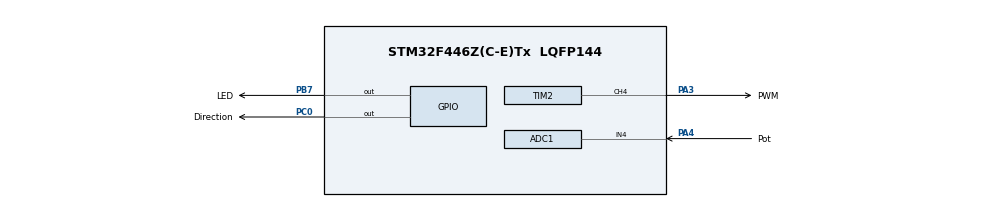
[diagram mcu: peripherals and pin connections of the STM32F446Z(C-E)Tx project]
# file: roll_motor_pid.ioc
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ADC1.Channel-2\#ChannelRegularConversion=ADC_CHANNEL_4
ADC1.ContinuousConvMode=ENABLE
ADC1.DMAContinuousRequests=ENABLE
ADC1.NbrOfConversionFlag=1
ADC1.Rank-2\#ChannelRegularConversion=1
ADC1.SamplingTime-2\#ChannelRegularConversion=ADC_SAMPLETIME_84CYCLES
ADC1.master=1
Dma.ADC1.0.Direction=DMA_PERIPH_TO_MEMORY
Dma.ADC1.0.FIFOMode=DMA_FIFOMODE_DISABLE
Dma.ADC1.0.Instance=DMA2_Stream0
Dma.ADC1.0.MemDataAlignment=DMA_MDATAALIGN_HALFWORD
Dma.ADC1.0.MemInc=DMA_MINC_ENABLE
Dma.ADC1.0.Mode=DMA_CIRCULAR
Dma.ADC1.0.PeriphDataAlignment=DMA_PDATAALIGN_HALFWORD
Dma.ADC1.0.PeriphInc=DMA_PINC_DISABLE
Dma.ADC1.0.Priority=DMA_PRIORITY_LOW
Dma.Request0=ADC1
Mcu.Family=STM32F4
Mcu.Name=STM32F446Z(C-E)Tx
Mcu.Package=LQFP144
NVIC.DMA2_Stream0_IRQn=true\:0\:0\:false\:false\:true\:false\:true\:true
NVIC.PriorityGroup=NVIC_PRIORITYGROUP_4
PA13.Mode=Serial_Wire
PA13.Signal=SYS_JTMS-SWDIO
PA14.Mode=Serial_Wire
PA14.Signal=SYS_JTCK-SWCLK
PA3.GPIO_Label=PWM
PA3.Signal=S_TIM2_CH4
PA4.GPIO_Label=Pot
PA4.Signal=ADCx_IN4
PB7.GPIO_Label=LED
PB7.Signal=GPIO_Output
PC0.GPIO_Label=Direction
PC0.Signal=GPIO_Output
ProjectManager.HeapSize=0x200
ProjectManager.StackSize=0x400
ProjectManager.TargetToolchain=STM32CubeIDE
RCC.CortexFreq_Value=16000000
RCC.USBFreq_Value=96000000
RCC.VCOOutputFreq_Value=192000000
SH.ADCx_IN4.0=ADC1_IN4,IN4
SH.S_TIM2_CH4.0=TIM2_CH4,PWM Generation4 CH4
TIM2.AutoReloadPreload=TIM_AUTORELOAD_PRELOAD_ENABLE
TIM2.Channel-PWM\ Generation4\ CH4=TIM_CHANNEL_4
TIM2.Period=799
TIM2.Pulse-PWM\ Generation4\ CH4=800
VP_TIM2_VS_ClockSourceINT.Mode=Internal
board=custom

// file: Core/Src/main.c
/* USER CODE BEGIN Header */
/**
  ******************************************************************************
  * @file           : main.c
  * @brief          : Main program body
  ******************************************************************************
  * @attention
  *
  * Copyright (c) 2026 STMicroelectronics.
  * All rights reserved.
  *
  * This software is licensed under terms that can be found in the LICENSE file
  * in the root directory of this software component.
  * If no LICENSE file comes with this software, it is provided AS-IS.
  *
  ******************************************************************************
  */
/* USER CODE END Header */
#include "main.h"
#include "roll_motor.h"

ADC_HandleTypeDef hadc1;
DMA_HandleTypeDef hdma_adc1;

TIM_HandleTypeDef htim2;

void SystemClock_Config(void);
static void MX_GPIO_Init(void);
static void MX_DMA_Init(void);
static void MX_TIM2_Init(void);
static void MX_ADC1_Init(void);

int main(void)
{

  /* MCU Configuration--------------------------------------------------------*/

  /* Reset of all peripherals, Initializes the Flash interface and the Systick. */
  HAL_Init();

  /* Configure the system clock */
  SystemClock_Config();

  /* Initialize all configured peripherals */

  MX_GPIO_Init();
  MX_DMA_Init();
  MX_TIM2_Init();
  MX_ADC1_Init();

  rm_init_motor();

  rm_find_center();
  HAL_Delay(2000);
  rm_rotate_degrees(90);
  HAL_Delay(2000);
  rm_rotate_degrees(-180);
  HAL_Delay(2000);
  rm_rotate_degrees(90);
  HAL_Delay(2000);
  rm_find_center(); //shouldnt move

  /* Infinite loop */
  /* USER CODE BEGIN WHILE */
  while (1)
  {
	rm_rotate_degrees(90);
	HAL_Delay(2000);
	rm_rotate_degrees(-180);
	HAL_Delay(2000);
    /* USER CODE END WHILE */

  }
}

void SystemClock_Config(void)
{
  RCC_OscInitTypeDef RCC_OscInitStruct = {0};
  RCC_ClkInitTypeDef RCC_ClkInitStruct = {0};

  /** Configure the main internal regulator output voltage
  */
  __HAL_RCC_PWR_CLK_ENABLE();
  __HAL_PWR_VOLTAGESCALING_CONFIG(PWR_REGULATOR_VOLTAGE_SCALE3);

  /** Initializes the RCC Oscillators according to the specified parameters
  * in the RCC_OscInitTypeDef structure.
  */
  RCC_OscInitStruct.OscillatorType = RCC_OSCILLATORTYPE_HSI;
  RCC_OscInitStruct.HSIState = RCC_HSI_ON;
  RCC_OscInitStruct.HSICalibrationValue = RCC_HSICALIBRATION_DEFAULT;
  RCC_OscInitStruct.PLL.PLLState = RCC_PLL_NONE;
  if (HAL_RCC_OscConfig(&RCC_OscInitStruct) != HAL_OK)
  {
    Error_Handler();
  }

  /** Initializes the CPU, AHB and APB buses clocks
  */
  RCC_ClkInitStruct.ClockType = RCC_CLOCKTYPE_HCLK|RCC_CLOCKTYPE_SYSCLK
                              |RCC_CLOCKTYPE_PCLK1|RCC_CLOCKTYPE_PCLK2;
  RCC_ClkInitStruct.SYSCLKSource = RCC_SYSCLKSOURCE_HSI;
  RCC_ClkInitStruct.AHBCLKDivider = RCC_SYSCLK_DIV1;
  RCC_ClkInitStruct.APB1CLKDivider = RCC_HCLK_DIV1;
  RCC_ClkInitStruct.APB2CLKDivider = RCC_HCLK_DIV1;

  if (HAL_RCC_ClockConfig(&RCC_ClkInitStruct, FLASH_LATENCY_0) != HAL_OK)
  {
    Error_Handler();
  }
}

static void MX_ADC1_Init(void)
{

  ADC_ChannelConfTypeDef sConfig = {0};

  /** Configure the global features of the ADC (Clock, Resolution, Data Alignment and number of conversion)
  */
  hadc1.Instance = ADC1;
  hadc1.Init.ClockPrescaler = ADC_CLOCK_SYNC_PCLK_DIV2;
  hadc1.Init.Resolution = ADC_RESOLUTION_12B;
  hadc1.Init.ScanConvMode = DISABLE;
  hadc1.Init.ContinuousConvMode = ENABLE;
  hadc1.Init.DiscontinuousConvMode = DISABLE;
  hadc1.Init.ExternalTrigConvEdge = ADC_EXTERNALTRIGCONVEDGE_NONE;
  hadc1.Init.ExternalTrigConv = ADC_SOFTWARE_START;
  hadc1.Init.DataAlign = ADC_DATAALIGN_RIGHT;
  hadc1.Init.NbrOfConversion = 1;
  hadc1.Init.DMAContinuousRequests = ENABLE;
  hadc1.Init.EOCSelection = ADC_EOC_SINGLE_CONV;
  if (HAL_ADC_Init(&hadc1) != HAL_OK)
  {
    Error_Handler();
  }

  /** Configure for the selected ADC regular channel its corresponding rank in the sequencer and its sample time.
  */
  sConfig.Channel = ADC_CHANNEL_4;
  sConfig.Rank = 1;
  sConfig.SamplingTime = ADC_SAMPLETIME_84CYCLES;
  if (HAL_ADC_ConfigChannel(&hadc1, &sConfig) != HAL_OK)
  {
    Error_Handler();
  }

}

static void MX_TIM2_Init(void)
{

  TIM_ClockConfigTypeDef sClockSourceConfig = {0};
  TIM_MasterConfigTypeDef sMasterConfig = {0};
  TIM_OC_InitTypeDef sConfigOC = {0};

  htim2.Instance = TIM2;
  htim2.Init.Prescaler = 0;
  htim2.Init.CounterMode = TIM_COUNTERMODE_UP;
  htim2.Init.Period = 799;
  htim2.Init.ClockDivision = TIM_CLOCKDIVISION_DIV1;
  htim2.Init.AutoReloadPreload = TIM_AUTORELOAD_PRELOAD_ENABLE;
  if (HAL_TIM_Base_Init(&htim2) != HAL_OK)
  {
    Error_Handler();
  }
  sClockSourceConfig.ClockSource = TIM_CLOCKSOURCE_INTERNAL;
  if (HAL_TIM_ConfigClockSource(&htim2, &sClockSourceConfig) != HAL_OK)
  {
    Error_Handler();
  }
  if (HAL_TIM_PWM_Init(&htim2) != HAL_OK)
  {
    Error_Handler();
  }
  sMasterConfig.MasterOutputTrigger = TIM_TRGO_RESET;
  sMasterConfig.MasterSlaveMode = TIM_MASTERSLAVEMODE_DISABLE;
  if (HAL_TIMEx_MasterConfigSynchronization(&htim2, &sMasterConfig) != HAL_OK)
  {
    Error_Handler();
  }
  sConfigOC.OCMode = TIM_OCMODE_PWM1;
  sConfigOC.Pulse = 800;
  sConfigOC.OCPolarity = TIM_OCPOLARITY_HIGH;
  sConfigOC.OCFastMode = TIM_OCFAST_DISABLE;
  if (HAL_TIM_PWM_ConfigChannel(&htim2, &sConfigOC, TIM_CHANNEL_4) != HAL_OK)
  {
    Error_Handler();
  }
  HAL_TIM_MspPostInit(&htim2);

}

static void MX_DMA_Init(void)
{

  /* DMA controller clock enable */
  __HAL_RCC_DMA2_CLK_ENABLE();

  /* DMA interrupt init */
  /* DMA2_Stream0_IRQn interrupt configuration */
  HAL_NVIC_SetPriority(DMA2_Stream0_IRQn, 0, 0);
  //HAL_NVIC_EnableIRQ(DMA2_Stream0_IRQn);

}

static void MX_GPIO_Init(void)
{
  GPIO_InitTypeDef GPIO_InitStruct = {0};

  /* GPIO Ports Clock Enable */
  __HAL_RCC_GPIOC_CLK_ENABLE();
  __HAL_RCC_GPIOA_CLK_ENABLE();
  __HAL_RCC_GPIOB_CLK_ENABLE();

  /*Configure GPIO pin Output Level */
  HAL_GPIO_WritePin(Direction_GPIO_Port, Direction_Pin, GPIO_PIN_RESET);

  /*Configure GPIO pin Output Level */
  HAL_GPIO_WritePin(LED_GPIO_Port, LED_Pin, GPIO_PIN_RESET);

  /*Configure GPIO pin : Direction_Pin */
  GPIO_InitStruct.Pin = Direction_Pin;
  GPIO_InitStruct.Mode = GPIO_MODE_OUTPUT_PP;
  GPIO_InitStruct.Pull = GPIO_NOPULL;
  GPIO_InitStruct.Speed = GPIO_SPEED_FREQ_LOW;
  HAL_GPIO_Init(Direction_GPIO_Port, &GPIO_InitStruct);

  /*Configure GPIO pin : LED_Pin */
  GPIO_InitStruct.Pin = LED_Pin;
  GPIO_InitStruct.Mode = GPIO_MODE_OUTPUT_PP;
  GPIO_InitStruct.Pull = GPIO_NOPULL;
  GPIO_InitStruct.Speed = GPIO_SPEED_FREQ_LOW;
  HAL_GPIO_Init(LED_GPIO_Port, &GPIO_InitStruct);

}

void Error_Handler(void)
{
  __disable_irq();
  while (1)
  {
  }
}
